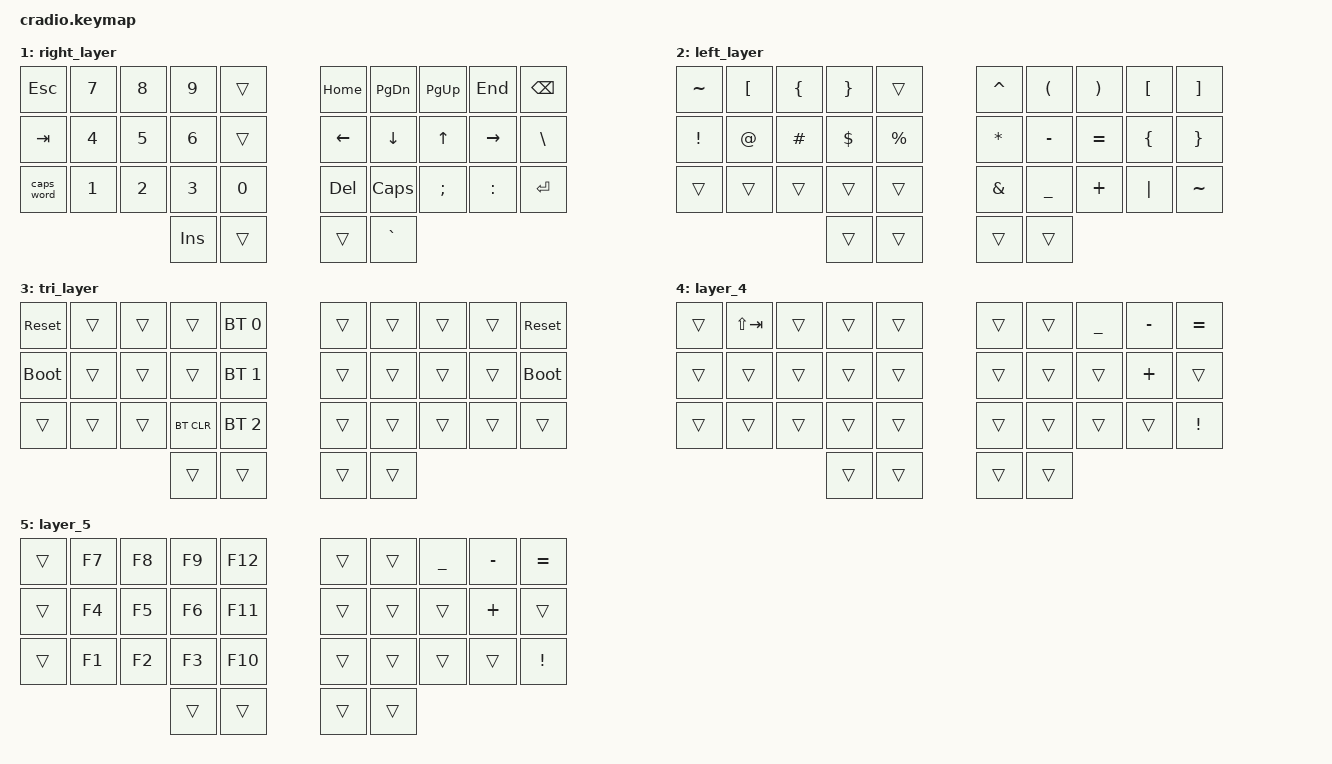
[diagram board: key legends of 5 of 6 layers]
//
// Keys to support https://zmk.dev/docs/keymaps/list-of-keycodes#keyboard
//

#include <behaviors.dtsi>
#include <dt-bindings/zmk/keys.h>
#include <dt-bindings/zmk/bt.h>
#include "zmk-helpers/helper.h"
#include "zmk-helpers/key-labels/34.h"
 /*                              34 KEY MATRIX / LAYOUT MAPPING

  ╭────────────────────┬────────────────────╮ ╭─────────────────────┬─────────────────────╮
  │  0   1   2   3   4 │  5   6   7   8   9 │ │ LT4 LT3 LT2 LT1 LT0 │ RT0 RT1 RT2 RT3 RT4 │
  │ 10  11  12  13  14 │ 15  16  17  18  19 │ │ LM4 LM3 LM2 LM1 LM0 │ RM0 RM1 RM2 RM3 RM4 │
  │ 20  21  22  23  24 │ 25  26  27  28  29 │ │ LB4 LB3 LB2 LB1 LB0 │ RB0 RB1 RB2 RB3 RB4 │
  ╰───────────╮ 30  31 │ 32  33 ╭───────────╯ ╰───────────╮ LH1 LH0 │ RH0 RH1 ╭───────────╯
              ╰────────┴────────╯                         ╰─────────┴─────────╯             */

// Home row mods macro
#define HRML(k1,k2,k3,k4) &ht LSHFT k1  &ht LALT k2  &ht LCTRL k3  &ht LGUI k4
#define HRMR(k1,k2,k3,k4) &ht RGUI k1  &ht RCTRL k2  &ht RALT k3  &ht RSHFT k4

/ {
    behaviors {
        ht: hold_tap {
            compatible = "zmk,behavior-hold-tap";
            #binding-cells = <2>;
            flavor = "tap-preferred";
            tapping-term-ms = <220>;
            quick-tap-ms = <150>;
            require-prior-idle-ms = <100>;
            bindings = <&kp>, <&kp>;
        };
        swap_tab: swap_tab {
            compatible = "zmk,behavior-tri-state";
            label = "SWAP_TAB";
            #binding-cells = <0>;
            bindings = <&kt LALT>, <&kp TAB>, <&kt LALT>;
            ignored-key-positions = <LT0>;
        };
        swap_lbk: swap_lbk {
            compatible = "zmk,behavior-tri-state";
            label = "SWAP_LBK";
            #binding-cells = <0>;
            bindings = <&mo 2>, <&kp RBKT>, <&mo 2>;
            ignored-key-positions = <LT0>;
        };
    };
    conditional_layers {
        compatible = "zmk,conditional-layers";
        tri_layer {
            if-layers = <1 2>;
            then-layer = <3>;
        };
    };
    combos {
        compatible = "zmk,combos";
        combo_f1key {
            timeout-ms = <50>;
            key-positions = <32 19>;
            bindings = <&kp F1>;
        };
    };

    keymap {
        compatible = "zmk,keymap";
        default_layer {
            bindings = <
        //╭──────────┬──────────┬──────────┬──────────┬──────────╮   ╭──────────┬──────────┬──────────┬──────────┬──────────╮
        //│  Q       │  W       │  E       │  R       │  T       │   │  Y       │  U       │  I       │  O       │  P       │
            &kp Q      &kp W      &kp E      &kp R      &kp T          &kp Y      &kp U      &kp I      &kp O      &kp P
        //├──────────┼──────────┼──────────┼──────────┼──────────┤   ├──────────┼──────────┼──────────┼──────────┼──────────┤
        //│  A       │  S       │  D       │  F       │  G       │   │  H       │  J       │  K       │  L       │ ' "      │
            HRML(A,        S,         D,         F)     &kp G          &kp H      HRMR(J,        K,         L,        SQT)
        //├──────────┼──────────┼──────────┼──────────┼──────────┤   ├──────────┼──────────┼──────────┼──────────┼──────────┤
        //│  Z       │  X       │  C       │  V       │  B       │   │  N       │  M       │ , <      │ . >      │          │
            &kp Z      &kp X      &kp C      &kp V      &kp B          &kp N      &kp M      &kp COMMA  &kp DOT    &kp FSLH
        //╰──────────┴──────────┴──────────┼──────────┼──────────┤   ├──────────┼──────────┼──────────┴──────────┴──────────╯
                                           &lt 4 ENTER &lt 1 TAB      &lt 2 SPACE &lt 5 BSPC
        //                                 ╰──────────┴──────────╯   ╰──────────┴──────────╯
            >;
        };

        right_layer {
            bindings = <
        //╭──────────┬──────────┬──────────┬──────────┬──────────╮   ╭──────────┬──────────┬──────────┬──────────┬──────────╮
        //│ ESC      │  1       │  2       │  3       │          │   │ HOME     │ PAGE DN  │ PAGE UP  │ END      │  <<      │
            &kp ESC    &kp N7    &kp N8     &kp N9     &trans        &kp HOME   &kp PG_DN  &kp PG_UP  &kp END    &kp BSPC
        //├──────────┼──────────┼──────────┼──────────┼──────────┤   ├──────────┼──────────┼──────────┼──────────┼──────────┤
        //│          │  4       │  5       │  6       │          │   │ LEFT     │ DOWN     │ UP       │ RIGHT    │  \       │
            &kp TAB    &kp N4     &kp N5     &kp N6     &trans        &kp LEFT   &kp DOWN   &kp UP   &kp RIGHT   &kp BSLH
        //├──────────┼──────────┼──────────┼──────────┼──────────┤   ├──────────┼──────────┼──────────┼──────────┼──────────┤
        //│ CAPS     │  7       │  8       │  9       │  0       │   │          │          │          │          │  /       │
           &caps_word  &kp N1     &kp N2     &kp N3     &kp N0        &kp DEL     &kp CAPS   &kp SEMI   &kp COLON  &kp ENTER
        //╰──────────┴──────────┴──────────┼──────────┼──────────┤   ├──────────┼──────────┼──────────┴──────────┴──────────╯
                                             &kp INS     &trans        &trans    &kp GRAVE
        //                                 ╰──────────┴──────────╯   ╰──────────┴──────────╯
            >;
        };

        left_layer {
            bindings = <
        //╭──────────┬──────────┬──────────┬──────────┬──────────╮   ╭──────────┬──────────┬──────────┬──────────┬──────────╮
        //│          │  [       │  {       │  }       │          │   │  ^       │  (       │  )       │  [       │  ]       │
            &kp TILDE  &kp LBKT   &kp LBRC   &kp RBRC   &trans         &kp CARET  &kp LPAR   &kp RPAR   &kp LBKT   &kp RBKT
        //├──────────┼──────────┼──────────┼──────────┼──────────┤   ├──────────┼──────────┼──────────┼──────────┼──────────┤
        //│  !       │  @       │  #       │  $       │  %       │   │  *       │  -       │  =       │  {       │  }       │
            &kp EXCL   &kp AT     &kp HASH   &kp DLLR   &kp PRCNT      &kp ASTRK  &kp MINUS  &kp EQUAL  &kp LBRC   &kp RBRC
        //├──────────┼──────────┼──────────┼──────────┼──────────┤   ├──────────┼──────────┼──────────┼──────────┼──────────┤
        //│          │          │          │          │          │   │  &       │  _       │  +       │  │       │          │
            &trans     &trans     &trans     &trans     &trans         &kp AMPS   &kp UNDER  &kp PLUS   &kp PIPE   &kp TILDE
        //╰──────────┴──────────┴──────────┼──────────┼──────────┤   ├──────────┼──────────┼──────────┴──────────┴──────────╯
                                             &trans     &trans         &trans     &trans                                 
        //                                 ╰──────────┴──────────╯   ╰──────────┴──────────╯
            >;
        };

        tri_layer {
            bindings = <
        //╭──────────┬──────────┬──────────┬──────────┬──────────╮   ╭──────────┬──────────┬──────────┬──────────┬──────────╮
        //│ RESET    │          │          │          │PROFILE 0 │   │          │          │          │          │  RESET   │
           &sys_reset  &trans     &trans     &trans    &bt BT_SEL 0    &trans     &trans     &trans     &trans    &sys_reset
        //├──────────┼──────────┼──────────┼──────────┼──────────┤   ├──────────┼──────────┼──────────┼──────────┼──────────┤
        //│BOOTLOADER│          │          │          │PROFILE 1 │   │          │          │          │          │BOOTLOADER│
          &bootloader  &trans     &trans     &trans    &bt BT_SEL 1    &trans     &trans     &trans     &trans    &bootloader
        //├──────────┼──────────┼──────────┼──────────┼──────────┤   ├──────────┼──────────┼──────────┼──────────┼──────────┤
        //│          │          │          │ CLEAR BT │PROFILE 2 │   │          │          │          │          │          │
            &trans     &trans     &trans    &bt BT_CLR &bt BT_SEL 2    &trans     &trans     &trans     &trans     &trans
        //╰──────────┴──────────┴──────────┼──────────┼──────────┤   ├──────────┼──────────┼──────────┴──────────┴──────────╯
                                             &trans     &trans         &trans     &trans
        //                                 ╰──────────┴──────────╯   ╰──────────┴──────────╯
            >;
        };

        layer_4 {
            bindings = <
        //╭──────────┬──────────┬──────────┬──────────┬──────────╮   ╭──────────┬──────────┬──────────┬──────────┬──────────╮
        //│          │          │          │          │          │   │          │          │          │          │          │
           &trans     &kp LS(TAB)  &trans    &trans    &trans          &trans     &trans     &kp UNDER   &kp MINUS  &kp EQUAL
        //├──────────┼──────────┼──────────┼──────────┼──────────┤   ├──────────┼──────────┼──────────┼──────────┼──────────┤
        //│          │          │          │          │          │   │          │          │          │          │          │
          &trans      &trans     &trans     &trans    &trans          &trans     &trans     &trans     &kp PLUS    &trans
        //├──────────┼──────────┼──────────┼──────────┼──────────┤   ├──────────┼──────────┼──────────┼──────────┼──────────┤
        //│          │          │          │          │          │   │          │          │          │          │          │
            &trans     &trans     &trans    &trans     &trans         &trans     &trans     &trans     &trans     &kp EXCL
        //╰──────────┴──────────┴──────────┼──────────┼──────────┤   ├──────────┼──────────┼──────────┴──────────┴──────────╯
                                             &trans     &trans         &trans     &trans
        //                                 ╰──────────┴──────────╯   ╰──────────┴──────────╯
            >;
        };

        layer_5 {
            bindings = <
        //╭──────────┬──────────┬──────────┬──────────┬──────────╮   ╭──────────┬──────────┬──────────┬──────────┬──────────╮
        //│          │          │          │          │          │   │          │          │          │          │          │
           &trans     &kp F7     &kp F8     &kp F9     &kp F12        &trans     &trans     &kp UNDER   &kp MINUS  &kp EQUAL
        //├──────────┼──────────┼──────────┼──────────┼──────────┤   ├──────────┼──────────┼──────────┼──────────┼──────────┤
        //│          │          │          │          │          │   │          │          │          │          │          │
          &trans      &kp F4     &kp F5     &kp F6     &kp F11        &trans     &trans     &trans     &kp PLUS    &trans
        //├──────────┼──────────┼──────────┼──────────┼──────────┤   ├──────────┼──────────┼──────────┼──────────┼──────────┤
        //│          │          │          │          │          │   │          │          │          │          │          │
            &trans     &kp F1     &kp F2    &kp F3     &kp F10        &trans     &trans     &trans     &trans     &kp EXCL
        //╰──────────┴──────────┴──────────┼──────────┼──────────┤   ├──────────┼──────────┼──────────┴──────────┴──────────╯
                                             &trans     &trans         &trans     &trans
        //                                 ╰──────────┴──────────╯   ╰──────────┴──────────╯
            >;
        };
    };
};
